# STM32H743 register map
File version: 2.4
CPU: CM7 r0p1, little endian, MPU, FPU, 4 interrupt priority bits
Registers are 32-bit, read-write, reset 0x0 unless marked. A register's access mark holds for its fields unless they carry their own. Offsets are from the block's base; [hi:lo] are bit positions; {n}, {i} and the like mark numbered series.

## PWR
Base 0x58024800
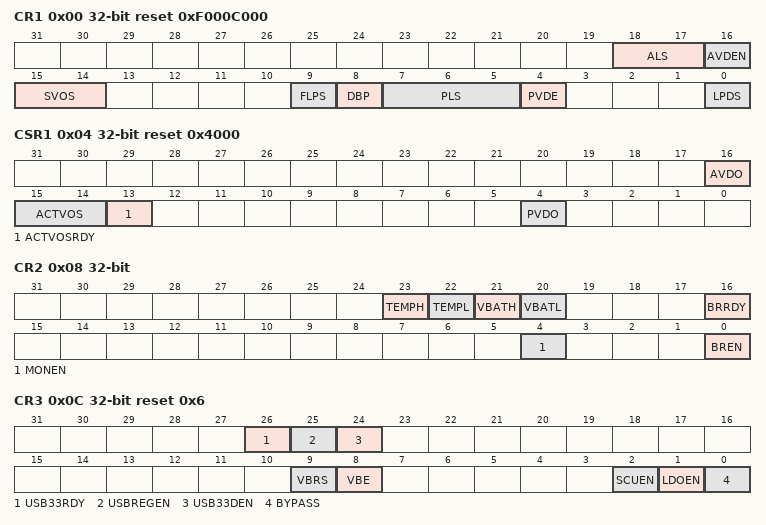
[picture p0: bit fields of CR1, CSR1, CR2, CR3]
0x00 CR1 reset 0xF000C000 — PWR 控制寄存器 1
  [18:17] ALS — 模拟电压检测器阈值选择 这些位用于选择 AVD 检测的电压阈值。
  [16] AVDEN — VDDA 外设电压监控器使能
  [15:14] SVOS — 系统停止模式电压调节选择 这些位控制系统 Stop 模式下的 VCORE 电压等级，以在功耗与性能之间取得最佳平衡。
  [9] FLPS — DStop 模式下 Flash 低功耗模式 此位用于在退出 DStop 模式时，在低功耗与重启时间之间取得最佳平衡。置位后，当 D1 域进入 DStop 模式时，Flash 存储器将进入低功耗模式。
  [8] DBP — 禁用备份域写保护 在复位状态下，RCC_BDCR 寄存器、RTC 寄存器（包括备份寄存器）、PWR_CR2 寄存器中的 BREN 和 MOEN 位均受到保护，防止寄生写入。必须将此位置 1 才能使能对这些寄存器的写访问。
  [7:5] PLS — 可编程电压检测器阈值选择 这些位用于选择 PVD 检测的电压阈值。注意：更多详细信息请参阅产品数据手册的电气特性章节。
  [4] PVDE — 可编程电压检测器使能
  [0] LPDS — 低功耗深度睡眠，配合 SVOS3 使用（SVOS4 和 SVOS5 始终使用低功耗模式，不受此位设置影响）
0x04 CSR1 ro reset 0x4000 — PWR 控制状态寄存器 1
  [16] AVDO — VDDA 模拟电压检测器输出 此位由硬件置位和清零。仅当 VDDA 上的 AVD 已通过 AVDEN 位使能时才有效。注意：由于 AVD 在待机模式下被禁用，因此在待机或复位后，此位保持为 0，直到 AVDEN 位置位。
  [15:14] ACTVOS — 当前应用于 VCORE 电压调节选择的 VOS。这些位反映最近一次写入 PMU 的 VOS 值。
  [13] ACTVOSRDY — 当前使用的 VOS 和 SDLEVEL 电压等级就绪位 当电压调节器和 SD 转换器均被禁用，且在 PWR 控制寄存器 3（PWR_CR3）中选择了旁路模式时，此位由硬件置 1。
  [4] PVDO — 可编程电压检测输出 此位由硬件置位和清零。仅当 PVD 已通过 PVDE 位使能时才有效。注意：由于 PVD 在待机模式下被禁用，因此在待机或复位后，此位保持为 0，直到 PVDE 位置位。
0x08 CR2 access per field — 此寄存器不受待机模式唤醒、RESET 信号和 VDD 上电复位的影响。仅由 VSW 上电复位和 VSWRST 复位来复位。当 RCC_BDCR 寄存器中的 VSWRST 位复位 VSW 域时，不得访问此寄存器。复位后，PWR_CR2 寄存器处于写保护状态。修改其内容之前，必须先将 PWR_CR1 寄存器中的 DBP 位置位以解除写保护。
  [23] TEMPH ro — 温度高于高阈值监控
  [22] TEMPL ro — 温度低于低阈值监控
  [21] VBATH ro — VBAT 电平高于高阈值监控
  [20] VBATL ro — VBAT 电平低于低阈值监控
  [16] BRRDY ro — 备份调压器就绪 此位由硬件置位，用于指示备份调压器已就绪。
  [4] MONEN rw — VBAT 和温度监控使能 置位后，VBAT 电源和温度监控被使能。
  [0] BREN rw — 备份调压器使能 置位后，备份调压器（用于在待机和 VBAT 模式下保持备份 RAM 内容）被使能。若 BREN 清零，则备份调压器关闭。备份 RAM 在运行和停止模式下仍可使用，但其内容将在待机和 VBAT 模式下丢失。若 BREN 置位，应用程序必须等待备份调压器就绪标志（BRRDY）置位，以表明写入 SRAM 的数据将在待机和 VBAT 模式下得到保持。
0x0C CR3 access per field reset 0x6 — 仅由上电复位（POR）复位，不受待机模式唤醒和 RESET 引脚的复位影响。此寄存器的低字节在 POR 后仅可写入一次，且应在更改 VOS 等级或 ck_sys 时钟频率之前写入。高字节无此限制。写入与 SDLEVEL、SDEXTHP、SDEN、LDOEN 和 BYPASS 位的无效组合（见表 9）对应的数据将被忽略：数据不会被写入，一次性写入机制将锁定该寄存器，任何后续写访问都将被忽略。默认电源配置将保持不变，PWR 控制状态寄存器 1（PWR_CSR1）中的 ACTVOSRDY 位将继续指示无效的电压等级。在写入新值之前，需要对系统进行下电再上电。
  [26] USB33RDY ro — USB 电源就绪
  [25] USBREGEN rw — USB 调压器使能
  [24] USB33DEN rw — VDD33USB 电压电平检测器使能
  [9] VBRS rw — VBAT 充电电阻选择
  [8] VBE rw — VBAT 充电使能
  [2] SCUEN rw — SD 转换器使能
  [1] LDOEN rw — 低压差调压器使能
  [0] BYPASS rw — 电源管理单元旁路
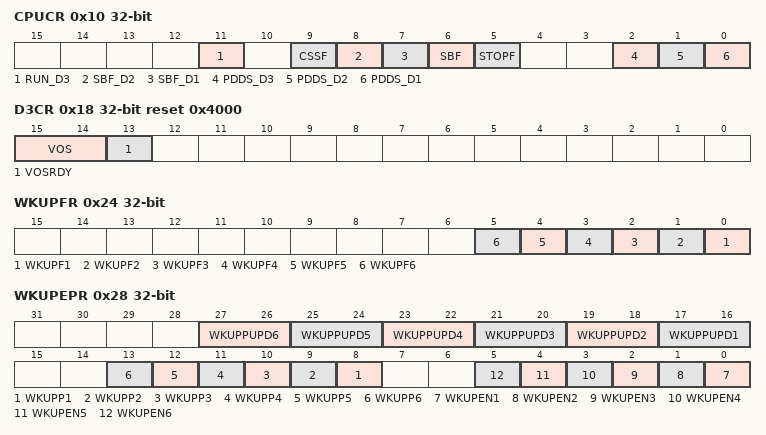
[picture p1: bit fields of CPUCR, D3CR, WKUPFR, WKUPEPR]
0x10 CPUCR access per field — 此寄存器用于控制 CPU1 的电源。
  [11] RUN_D3 rw — 无论 CPU 子系统处于何种模式，保持系统 D3 域处于运行模式
  [9] CSSF rw — 清除 D1 域 CPU1 的 Standby、Stop 和 HOLD 标志（读取时始终为 0）此位由硬件清零为 0。
  [8] SBF_D2 ro — D2 域 DStandby 标志 此位由硬件置位，可通过任意系统复位或将 CPU1 CSSF 位置位来清零。一旦置位，仅当 D2 域不再处于 DStandby 模式时才能清除此位。
  [7] SBF_D1 ro — D1 域 DStandby 标志 此位由硬件置位，可通过任意系统复位或将 CPU1 CSSF 位置位来清零。一旦置位，仅当 D1 域不再处于 DStandby 模式时才能清除此位。
  [6] SBF ro — 系统待机标志 此位由硬件置位，仅可通过上电复位（POR）或将 CPU1 CSSF 位置位来清零。
  [5] STOPF ro — STOP 标志 此位由硬件置位，仅可通过任意复位或将 CPU1 CSSF 位置位来清零。
  [2] PDDS_D3 rw — 系统 D3 域断电深度睡眠。此位允许 CPU1 定义系统 D3 域的深度睡眠模式。
  [1] PDDS_D2 rw — D2 域断电深度睡眠。此位允许 CPU1 定义 D2 域的深度睡眠模式。
  [0] PDDS_D1 rw — D1 域断电深度睡眠选择。此位允许 CPU1 定义 D1 域的深度睡眠模式。
0x18 D3CR access per field reset 0x4000 — 此寄存器用于控制 D3 域的电源。复位后，软件读取 VOSRDY 将为 1。
  [15:14] VOS rw — 根据性能选择电压调节 这些位控制 VCORE 电压等级，用于在功耗与性能之间取得最佳平衡：提高性能时，应在提升系统频率之前先更改电压调节等级。降低性能时，应先降低系统频率，再更改电压调节等级。
  [13] VOSRDY ro — VCORE 电压调节输出选择的 VOS 就绪位。当在 PWR 控制寄存器 3（PWR_CR3）中选择旁路模式时，此位由硬件置 1。
0x20 WKUPCR — 仅由系统复位复位，不受待机模式唤醒影响。写入此寄存器需要 5 个等待状态（清除 PWR_WKUPFR 中的 WKUPF 位时，AHB 写访问将在 WKUPF 被清除后完成）。
  [5:0] WKUPC — 清除 WKUP 唤醒引脚标志。这些位读取时始终为 0。
0x24 WKUPFR — 仅由系统复位复位，不受待机模式唤醒影响
  [n-1] WKUPF{n} (n=1..6) — 唤醒引脚 WKUPF 标志。此位由硬件置位，仅可通过复位引脚或将 PWR 唤醒清除寄存器（PWR_WKUPCR）中的 WKUPCn+1 位置位来清零。
0x28 WKUPEPR — 仅由系统复位复位，不受待机模式唤醒影响
  [27:26] WKUPPUPD6 — WKUP(truncate(n/2)-7) 唤醒引脚上下拉配置 这些位定义当 WKUPEN(truncate(n/2)-7) = 1 时使用的 I/O 焊盘上下拉配置。相关 GPIO 端口的上下拉配置应设为相同的值或设为 00。唤醒引脚的上下拉配置在待机模式下保持不变。
  [2n+15:2n+14] WKUPPUPD{n} (n=1..5) — 唤醒引脚上下拉配置
  [n+7] WKUPP{n} (n=1..6) — WKUPn-7 唤醒引脚极性位 这些位定义 WKUPn-7 外部唤醒引脚用于事件检测的极性。
  [n-1] WKUPEN{n} (n=1..6) — 使能唤醒引脚 WKUPn+1 每个位由软件置位和清零。注意：若在 WKUPn+1 引脚电平已为高（且 WKUPPn+1 选择上升沿）或已为低（且 WKUPPn+1 选择下降沿）时，使能 WKUPn+1 引脚（通过置位 WKUPENn+1 位），则会检测到一个额外的唤醒事件。
